# StarFive VisionFive 2 v1.3b register map
File version: 0.1
Registers are 32-bit, read-write, no defined reset value unless marked. A register's access mark holds for its fields unless they carry their own. Offsets are from the block's base; [hi:lo] are bit positions; {n}, {i} and the like mark numbered series.

## starfive_jh7110_sys_syscon_0 — From starfive,jh7110-sys-syscon, peripheral generator
Base 0x13030000
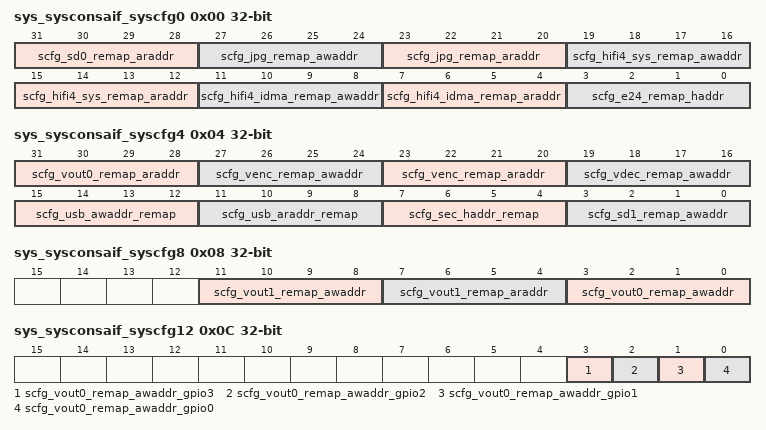
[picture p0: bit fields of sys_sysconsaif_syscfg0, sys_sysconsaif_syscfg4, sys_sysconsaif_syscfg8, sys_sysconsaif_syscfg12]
0x00 sys_sysconsaif_syscfg0
  [31:28] scfg_sd0_remap_araddr, [27:24] scfg_jpg_remap_awaddr, [23:20] scfg_jpg_remap_araddr, [19:16] scfg_hifi4_sys_remap_awaddr, [15:12] scfg_hifi4_sys_remap_araddr, [11:8] scfg_hifi4_idma_remap_awaddr, [7:4] scfg_hifi4_idma_remap_araddr, [3:0] scfg_e24_remap_haddr
0x04 sys_sysconsaif_syscfg4
  [31:28] scfg_vout0_remap_araddr, [27:24] scfg_venc_remap_awaddr, [23:20] scfg_venc_remap_araddr, [19:16] scfg_vdec_remap_awaddr, [15:12] scfg_usb_awaddr_remap, [11:8] scfg_usb_araddr_remap, [7:4] scfg_sec_haddr_remap, [3:0] scfg_sd1_remap_awaddr
0x08 sys_sysconsaif_syscfg8
  [11:8] scfg_vout1_remap_awaddr, [7:4] scfg_vout1_remap_araddr, [3:0] scfg_vout0_remap_awaddr
0x0C sys_sysconsaif_syscfg12 — SYS SYSCONSAIF SYSCFG 12: Set the GPIO voltage of all the 4 GPIO groups in this register
  [3] scfg_vout0_remap_awaddr_gpio3 — 0: GPIO Group 3 (GPIO7-20) voltage select 3.3V, 1: GPIO Group 3 (GPIO7-20) voltage select 1.8V
  [2] scfg_vout0_remap_awaddr_gpio2 — 0: GPIO Group 2 (GPIO0-6) voltage select 3.3V, 1: GPIO Group 2 (GPIO0-6) voltage select 1.8V
  [1] scfg_vout0_remap_awaddr_gpio1 — 0: GPIO Group 1 (GPIO36-63) voltage select 3.3V, 1: GPIO Group 1 (GPIO36-63) voltage select 1.8V
  [0] scfg_vout0_remap_awaddr_gpio0 — 0: GPIO Group 0 (GPIO21-35) voltage select 3.3V, 1: GPIO Group 0 (GPIO21-35) voltage select 1.8V
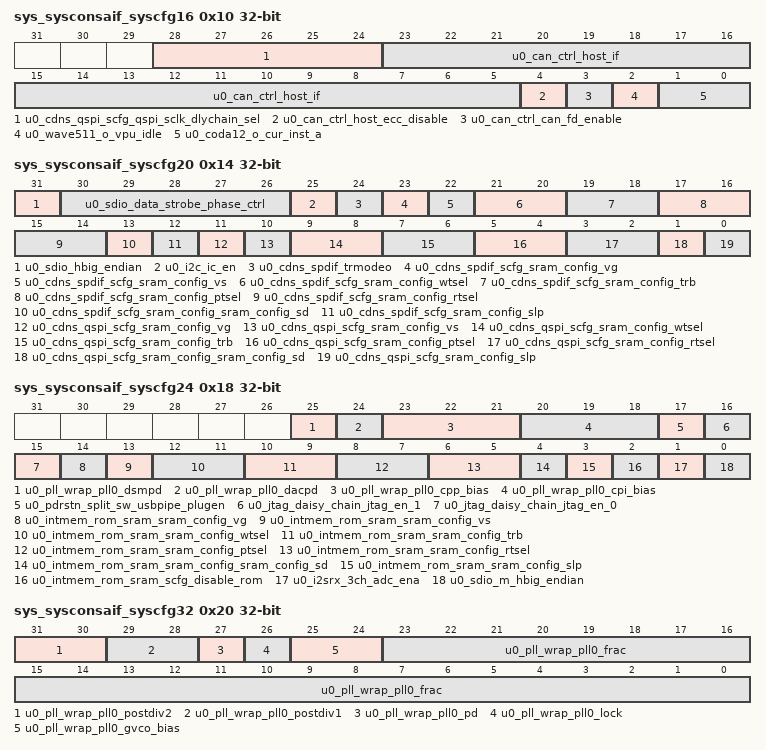
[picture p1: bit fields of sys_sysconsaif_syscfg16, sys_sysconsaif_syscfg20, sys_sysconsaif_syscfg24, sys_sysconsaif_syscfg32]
0x10 sys_sysconsaif_syscfg16
  [28:24] u0_cdns_qspi_scfg_qspi_sclk_dlychain_sel ro — des_qspi_sclk_dla: clock delay
  [23:5] u0_can_ctrl_host_if ro
  [4] u0_can_ctrl_host_ecc_disable
  [3] u0_can_ctrl_can_fd_enable
  [2] u0_wave511_o_vpu_idle ro — VPU monitoring signal
  [1:0] u0_coda12_o_cur_inst_a ro — Tie 0 in JPU internal, do not care
0x14 sys_sysconsaif_syscfg20
  [31] u0_sdio_hbig_endian — AHB bus interface endianness: 1: Big-endian AHB bus interface, 0: Little-endian AHB bus interface
  [30:26] u0_sdio_data_strobe_phase_ctrl — Data strobe delay chain select
  [25] u0_i2c_ic_en ro — I2C interface enable
  [24] u0_cdns_spdif_trmodeo ro — 1 for transmitter 0 for receiver
  [23] u0_cdns_spdif_scfg_sram_config_vg — SRAM/ROM configuration. VG: timing setting for debug purpose, default is 1'b1.
  [22] u0_cdns_spdif_scfg_sram_config_vs — SRAM/ROM configuration. VS: timing setting for debug purpose, default is 1'b1.
  [21:20] u0_cdns_spdif_scfg_sram_config_wtsel — SRAM/ROM configuration. WTSEL: timing setting for debug purpose, default is 2'b01.
  [19:18] u0_cdns_spdif_scfg_sram_config_trb — SRAM/ROM configuration. TRB: timing setting for debug purpose, default is 2'b01.
  [17:16] u0_cdns_spdif_scfg_sram_config_ptsel — SRAM/ROM configuration. PTSEL: timing setting for debug purpose, default is 2'b01.
  [15:14] u0_cdns_spdif_scfg_sram_config_rtsel — SRAM/ROM configuration. RTSEL: timing setting for debug purpose, default is 2'b01.
  [13] u0_cdns_spdif_scfg_sram_config_sram_config_sd — SRAM/ROM configuration. SD: shutdown enable, high active, default is low.
  [12] u0_cdns_spdif_scfg_sram_config_slp — SRAM/ROM configuration. SLP: sleep enable, high active, default is low.
  [11] u0_cdns_qspi_scfg_sram_config_vg — SRAM/ROM configuration. VG: timing setting for debug purpose, default is 1'b1.
  [10] u0_cdns_qspi_scfg_sram_config_vs — SRAM/ROM configuration. VS: timing setting for debug purpose, default is 1'b1.
  [9:8] u0_cdns_qspi_scfg_sram_config_wtsel — SRAM/ROM configuration. WTSEL: timing setting for debug purpose, default is 2'b01.
  [7:6] u0_cdns_qspi_scfg_sram_config_trb — SRAM/ROM configuration. TRB: timing setting for debug purpose, default is 2'b01.
  [5:4] u0_cdns_qspi_scfg_sram_config_ptsel — SRAM/ROM configuration. PTSEL: timing setting for debug purpose, default is 2'b01.
  [3:2] u0_cdns_qspi_scfg_sram_config_rtsel — SRAM/ROM configuration. RTSEL: timing setting for debug purpose, default is 2'b01.
  [1] u0_cdns_qspi_scfg_sram_config_sram_config_sd — SRAM/ROM configuration. SD: shutdown enable, high active, default is low.
  [0] u0_cdns_qspi_scfg_sram_config_slp — SRAM/ROM configuration. SLP: sleep enable, high active, default is low.
0x18 sys_sysconsaif_syscfg24
  [25] u0_pll_wrap_pll0_dsmpd
  [24] u0_pll_wrap_pll0_dacpd
  [23:21] u0_pll_wrap_pll0_cpp_bias
  [20:18] u0_pll_wrap_pll0_cpi_bias
  [17] u0_pdrstn_split_sw_usbpipe_plugen
  [16] u0_jtag_daisy_chain_jtag_en_1
  [15] u0_jtag_daisy_chain_jtag_en_0
  [14] u0_intmem_rom_sram_sram_config_vg — SRAM/ROM configuration. VG: timing setting for debug purpose, default is 1'b1.
  [13] u0_intmem_rom_sram_sram_config_vs — SRAM/ROM configuration. VS: timing setting for debug purpose, default is 1'b1.
  [12:11] u0_intmem_rom_sram_sram_config_wtsel — SRAM/ROM configuration. WTSEL: timing setting for debug purpose, default is 2'b01.
  [10:9] u0_intmem_rom_sram_sram_config_trb — SRAM/ROM configuration. TRB: timing setting for debug purpose, default is 2'b01.
  [8:7] u0_intmem_rom_sram_sram_config_ptsel — SRAM/ROM configuration. PTSEL: timing setting for debug purpose, default is 2'b01.
  [6:5] u0_intmem_rom_sram_sram_config_rtsel — SRAM/ROM configuration. RTSEL: timing setting for debug purpose, default is 2'b01.
  [4] u0_intmem_rom_sram_sram_config_sram_config_sd — SRAM/ROM configuration. SD: shutdown enable, high active, default is low.
  [3] u0_intmem_rom_sram_sram_config_slp — SRAM/ROM configuration. SLP: sleep enable, high active, default is low.
  [2] u0_intmem_rom_sram_scfg_disable_rom
  [1] u0_i2srx_3ch_adc_ena
  [0] u0_sdio_m_hbig_endian — AHB master bus interface endianess: 1: Big-endian AHB bus interface, 0: Little-endian AHB bus interface
0x1C sys_sysconsaif_syscfg28
  [11:0] u0_pll_wrap_pll0_fbdiv
0x20 sys_sysconsaif_syscfg32
  [31:30] u0_pll_wrap_pll0_postdiv2, [29:28] u0_pll_wrap_pll0_postdiv1, [27] u0_pll_wrap_pll0_pd, [26] u0_pll_wrap_pll0_lock ro, [25:24] u0_pll_wrap_pll0_gvco_bias, [23:0] u0_pll_wrap_pll0_frac
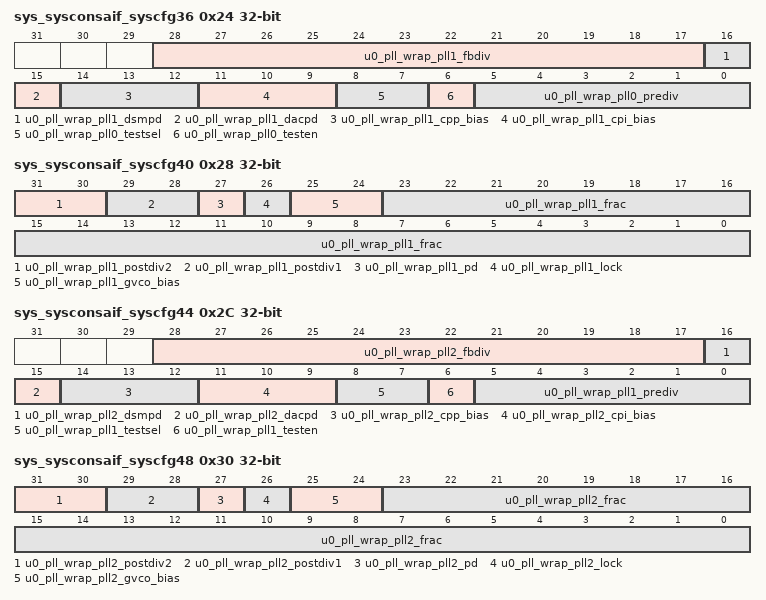
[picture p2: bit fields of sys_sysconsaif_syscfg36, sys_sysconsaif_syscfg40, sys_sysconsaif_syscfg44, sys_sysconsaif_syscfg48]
0x24 sys_sysconsaif_syscfg36
  [28:17] u0_pll_wrap_pll1_fbdiv, [16] u0_pll_wrap_pll1_dsmpd, [15] u0_pll_wrap_pll1_dacpd, [14:12] u0_pll_wrap_pll1_cpp_bias, [11:9] u0_pll_wrap_pll1_cpi_bias, [8:7] u0_pll_wrap_pll0_testsel, [6] u0_pll_wrap_pll0_testen, [5:0] u0_pll_wrap_pll0_prediv
0x28 sys_sysconsaif_syscfg40
  [31:30] u0_pll_wrap_pll1_postdiv2, [29:28] u0_pll_wrap_pll1_postdiv1, [27] u0_pll_wrap_pll1_pd, [26] u0_pll_wrap_pll1_lock ro, [25:24] u0_pll_wrap_pll1_gvco_bias, [23:0] u0_pll_wrap_pll1_frac
0x2C sys_sysconsaif_syscfg44
  [28:17] u0_pll_wrap_pll2_fbdiv, [16] u0_pll_wrap_pll2_dsmpd, [15] u0_pll_wrap_pll2_dacpd, [14:12] u0_pll_wrap_pll2_cpp_bias, [11:9] u0_pll_wrap_pll2_cpi_bias, [8:7] u0_pll_wrap_pll1_testsel, [6] u0_pll_wrap_pll1_testen, [5:0] u0_pll_wrap_pll1_prediv
0x30 sys_sysconsaif_syscfg48
  [31:30] u0_pll_wrap_pll2_postdiv2, [29:28] u0_pll_wrap_pll2_postdiv1, [27] u0_pll_wrap_pll2_pd, [26] u0_pll_wrap_pll2_lock ro, [25:24] u0_pll_wrap_pll2_gvco_bias, [23:0] u0_pll_wrap_pll2_frac
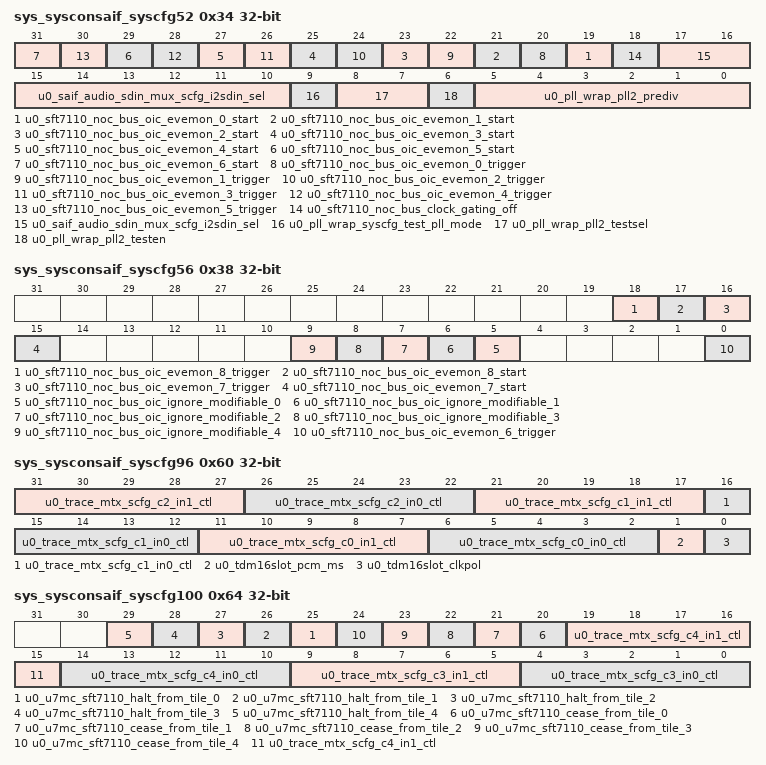
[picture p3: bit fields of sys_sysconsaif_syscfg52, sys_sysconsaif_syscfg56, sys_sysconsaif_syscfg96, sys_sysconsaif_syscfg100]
0x34 sys_sysconsaif_syscfg52
  [2n+19] u0_sft7110_noc_bus_oic_evemon_{n}_start (n=0..6)
  [2n+20] u0_sft7110_noc_bus_oic_evemon_{n}_trigger ro (n=0..5)
  [18] u0_sft7110_noc_bus_clock_gating_off
  [17:10] u0_saif_audio_sdin_mux_scfg_i2sdin_sel
  [9] u0_pll_wrap_syscfg_test_pll_mode — PLL test mode, only used for PLL BIST through jtag2apb
  [8:7] u0_pll_wrap_pll2_testsel
  [6] u0_pll_wrap_pll2_testen
  [5:0] u0_pll_wrap_pll2_prediv
0x38 sys_sysconsaif_syscfg56
  [18] u0_sft7110_noc_bus_oic_evemon_8_trigger ro, [17] u0_sft7110_noc_bus_oic_evemon_8_start, [16] u0_sft7110_noc_bus_oic_evemon_7_trigger ro, [15] u0_sft7110_noc_bus_oic_evemon_7_start, [n+5] u0_sft7110_noc_bus_oic_ignore_modifiable_{n} (n=0..4), [0] u0_sft7110_noc_bus_oic_evemon_6_trigger ro
0x3C sys_sysconsaif_syscfg60
  [31:0] u0_sft7110_noc_bus_oic_qch_clock_stop_threshold_0
0x40 sys_sysconsaif_syscfg64
  [31:0] u0_sft7110_noc_bus_oic_qch_clock_stop_threshold_1
0x44 sys_sysconsaif_syscfg68
  [31:0] u0_sft7110_noc_bus_oic_qch_clock_stop_threshold_2
0x48 sys_sysconsaif_syscfg72
  [31:0] u0_sft7110_noc_bus_oic_qch_clock_stop_threshold_3
0x4C sys_sysconsaif_syscfg76
  [31:0] u0_sft7110_noc_bus_oic_qch_clock_stop_threshold_4
0x50 sys_sysconsaif_syscfg80
  [31:0] u0_sft7110_noc_bus_oic_qch_clock_stop_threshold_5
0x54 sys_sysconsaif_syscfg84
  [31:0] u0_sft7110_noc_bus_oic_qch_clock_stop_threshold_6
0x58 sys_sysconsaif_syscfg88
  [31:0] u0_sft7110_noc_bus_oic_qch_clock_stop_threshold_7
0x5C sys_sysconsaif_syscfg92
  [31:0] u0_sft7110_noc_bus_oic_qch_clock_stop_threshold_8
0x60 sys_sysconsaif_syscfg96
  [31:27] u0_trace_mtx_scfg_c2_in1_ctl, [26:22] u0_trace_mtx_scfg_c2_in0_ctl, [21:17] u0_trace_mtx_scfg_c1_in1_ctl, [16:12] u0_trace_mtx_scfg_c1_in0_ctl, [11:7] u0_trace_mtx_scfg_c0_in1_ctl, [6:2] u0_trace_mtx_scfg_c0_in0_ctl, [1] u0_tdm16slot_pcm_ms ro, [0] u0_tdm16slot_clkpol ro
0x64 sys_sysconsaif_syscfg100
  [n+25] u0_u7mc_sft7110_halt_from_tile_{n} ro (n=0..4), [n+20] u0_u7mc_sft7110_cease_from_tile_{n} ro (n=0..4), [19:15] u0_trace_mtx_scfg_c4_in1_ctl, [14:10] u0_trace_mtx_scfg_c4_in0_ctl, [9:5] u0_trace_mtx_scfg_c3_in1_ctl, [4:0] u0_trace_mtx_scfg_c3_in0_ctl
0x68 sys_sysconsaif_syscfg104
  [31:0] u0_u7mc_sft7110_reset_vector_1_31_0
0x6C sys_sysconsaif_syscfg108
  [3:0] u0_u7mc_sft7110_reset_vector_1_35_32
0x70 sys_sysconsaif_syscfg112
  [31:0] u0_u7mc_sft7110_reset_vector_2_31_0
0x74 sys_sysconsaif_syscfg116
  [3:0] u0_u7mc_sft7110_reset_vector_2_35_32
0x78 sys_sysconsaif_syscfg120
  [31:0] u0_u7mc_sft7110_reset_vector_3_31_0
0x7C sys_sysconsaif_syscfg124
  [3:0] u0_u7mc_sft7110_reset_vector_3_35_32
0x80 sys_sysconsaif_syscfg128
  [31:0] u0_u7mc_sft7110_reset_vector_4_31_0
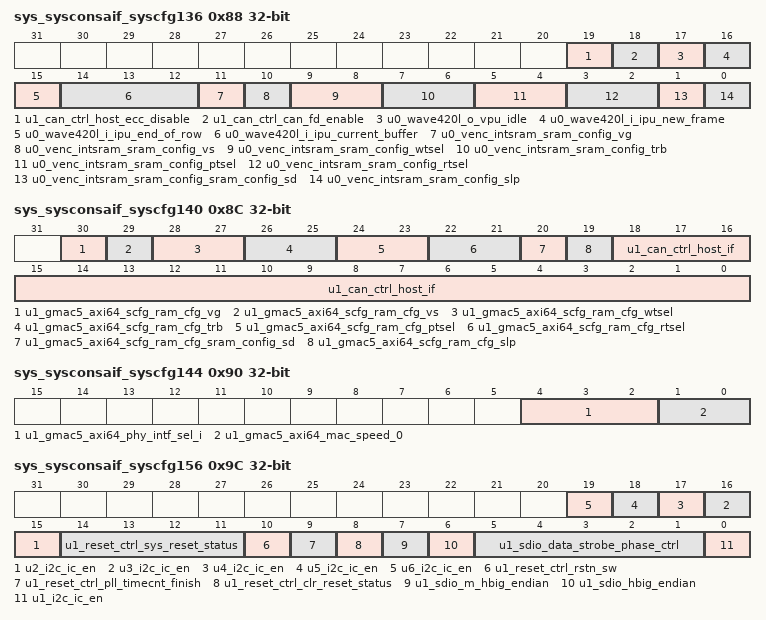
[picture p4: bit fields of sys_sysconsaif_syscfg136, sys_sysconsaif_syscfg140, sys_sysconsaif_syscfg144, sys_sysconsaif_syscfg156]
0x88 sys_sysconsaif_syscfg136
  [19] u1_can_ctrl_host_ecc_disable
  [18] u1_can_ctrl_can_fd_enable
  [17] u0_wave420l_o_vpu_idle ro — VPU monitoring signal. This signal gives out an opposite value of VPU_BUSY register.
  [16] u0_wave420l_i_ipu_new_frame — This signal is flipped every time when the IPU completes writing a new frame.
  [15] u0_wave420l_i_ipu_end_of_row — This signal is flipped every time when the IPU completes writing a row.
  [14:12] u0_wave420l_i_ipu_current_buffer — This signal indicates which buffer is currently active so that the VPU can correctly use the ipu_end_of_row signal for row counter.
  [11] u0_venc_intsram_sram_config_vg — SRAM/ROM configuration. VG: timing setting for debug purpose, default is 1'b1.
  [10] u0_venc_intsram_sram_config_vs — SRAM/ROM configuration. VS: timing setting for debug purpose, default is 1'b1.
  [9:8] u0_venc_intsram_sram_config_wtsel — SRAM/ROM configuration. WTSEL: timing setting for debug purpose, default is 2'b01.
  [7:6] u0_venc_intsram_sram_config_trb — SRAM/ROM configuration. TRB: timing setting for debug purpose, default is 2'b01.
  [5:4] u0_venc_intsram_sram_config_ptsel — SRAM/ROM configuration. PTSEL: timing setting for debug purpose, default is 2'b01.
  [3:2] u0_venc_intsram_sram_config_rtsel — SRAM/ROM configuration. RTSEL: timing setting for debug purpose, default is 2'b01.
  [1] u0_venc_intsram_sram_config_sram_config_sd — SRAM/ROM configuration. SD: shutdown enable, high active, default is low.
  [0] u0_venc_intsram_sram_config_slp — SRAM/ROM configuration. SLP: sleep enable, high active, default is low.
0x8C sys_sysconsaif_syscfg140
  [30] u1_gmac5_axi64_scfg_ram_cfg_vg — SRAM/ROM configuration. VG: timing setting for debug purpose, default is 1'b1.
  [29] u1_gmac5_axi64_scfg_ram_cfg_vs — SRAM/ROM configuration. VS: timing setting for debug purpose, default is 1'b1.
  [28:27] u1_gmac5_axi64_scfg_ram_cfg_wtsel — SRAM/ROM configuration. WTSEL: timing setting for debug purpose, default is 2'b01.
  [26:25] u1_gmac5_axi64_scfg_ram_cfg_trb — SRAM/ROM configuration. TRB: timing setting for debug purpose, default is 2'b01.
  [24:23] u1_gmac5_axi64_scfg_ram_cfg_ptsel — SRAM/ROM configuration. PTSEL: timing setting for debug purpose, default is 2'b01.
  [22:21] u1_gmac5_axi64_scfg_ram_cfg_rtsel — SRAM/ROM configuration. RTSEL: timing setting for debug purpose, default is 2'b01.
  [20] u1_gmac5_axi64_scfg_ram_cfg_sram_config_sd — SRAM/ROM configuration. SD: shutdown enable, high active, default is low.
  [19] u1_gmac5_axi64_scfg_ram_cfg_slp — SRAM/ROM configuration. SLP: sleep enable, high active, default is low.
  [18:0] u1_can_ctrl_host_if ro
0x90 sys_sysconsaif_syscfg144
  [4:2] u1_gmac5_axi64_phy_intf_sel_i — Active PHY Selected | When you have multiple GMAC PHY interfaces in your configuration, this field indicates the sampled value of the PHY selector during reset de-assertion. | Values: 0x0:(GMII or MII), 0x01:RGMII, 0x2:SGMII, 0x3:TBI, 0x4:RMII, 0x5:RTBI, 0x6:SMII, 0x7:REVMII
  [1:0] u1_gmac5_axi64_mac_speed_0 ro
0x94 sys_sysconsaif_syscfg148
  [31:0] u1_gmac5_axi64_ptp_timestamp_o_31_0 ro
0x98 sys_sysconsaif_syscfg152
  [31:0] u1_gmac5_axi64_ptp_timestamp_o_63_32 ro
0x9C sys_sysconsaif_syscfg156
  [n+13] u{n}_i2c_ic_en ro (n=2..6) — I2C interface enable.
  [14:11] u1_reset_ctrl_sys_reset_status ro
  [10] u1_reset_ctrl_rstn_sw
  [9] u1_reset_ctrl_pll_timecnt_finish ro
  [8] u1_reset_ctrl_clr_reset_status
  [7] u1_sdio_m_hbig_endian — AHB bus interface endianness: 1: Big-endian AHB bus interface, 0: Little-endian AHB bus interface
  [6] u1_sdio_hbig_endian — AHB bus interface endianness: 1: Big-endian AHB bus interface, 0: Little-endian AHB bus interface
  [5:1] u1_sdio_data_strobe_phase_ctrl — Data strobe delay chain select.
  [0] u1_i2c_ic_en ro — I2C interface enable.
